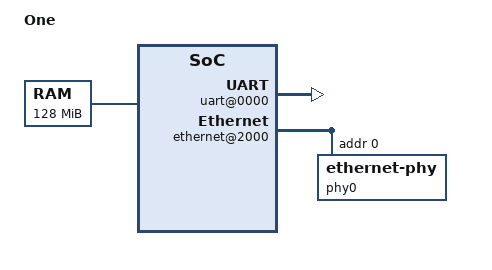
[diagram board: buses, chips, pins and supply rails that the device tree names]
/* Device Tree Source for Milkymist One
 *
 * Author: Michael Walle <michael@walle.cc>
 *
 * This program is free software; you can redistribute it and/or modify it
 * under the terms of the GNU General Public License version 2 as published
 * by the Free Software Foundation.
 */

/dts-v1/;

/ {
	#address-cells = <1>;
	#size-cells = <1>;
	model = "One";
	compatible = "milkymist,one";

	cpus {
		#address-cells = <1>;
		#size-cells = <0>;

		cpu@0 {
			device_type = "cpu";
			compatible = "lattice,mico32";
			reg = <0>;
			clock-frequency = <83333333>;
			i-cache-line-size = <16>;
			d-cache-line-size = <16>;
			i-cache-size = <4096>;
			d-cache-size = <4096>;

			pic: pic {
				#interrupt-cells = <1>;
				#address-cells = <0>;
				compatible = "lattice,mico32-pic";
				interrupt-controller;
			};
		};
	};

	memory@40000000 {
		device_type = "memory";
		reg = <0x40000000 0x08000000>;	/* 128MB */
	};

	csr-bus@e0000000 {
		#address-cells = <1>;
		#size-cells = <1>;
		ranges = <0x0 0xe0000000 0x100000>;
		compatible = "milkymist,csr-bus";

		uart@0000 {
			device_type = "serial";
			compatible = "milkymist,uart";
			clock-frequency = <83333333>;
			reg = <0x0000 0x800>;
			interrupts = <0>;
			interrupt-parent = <&pic>;
		};

		ethernet@2000 {
			#address-cells = <1>;
			#size-cells = <0>;
			compatible = "milkymist,minimac3";
			reg = <0x2000 0x800>;
			interrupts = <2>;
			interrupt-parent = <&pic>;

			phy0: ethernet-phy@0 {
				device_type = "ethernet-phy";
				reg = <0>;
				phy = <&phy0>;
				local-mac-address = [ 00 00 00 00 00 00 ];
			};
		};
	};
	chosen {
		bootargs = "root=/dev/ram0 rootfstype=ext2 console=ttyS0";
	};
};
